# CH32V30xxx register map
Vendor: WCH Ltd.; File version: 1.0
Registers are 32-bit, read-write, reset 0x0 unless marked. A register's access mark holds for its fields unless they carry their own. Offsets are from the block's base; [hi:lo] are bit positions.

## FSMC — Flexible static memory controller
Base 0xA0000000
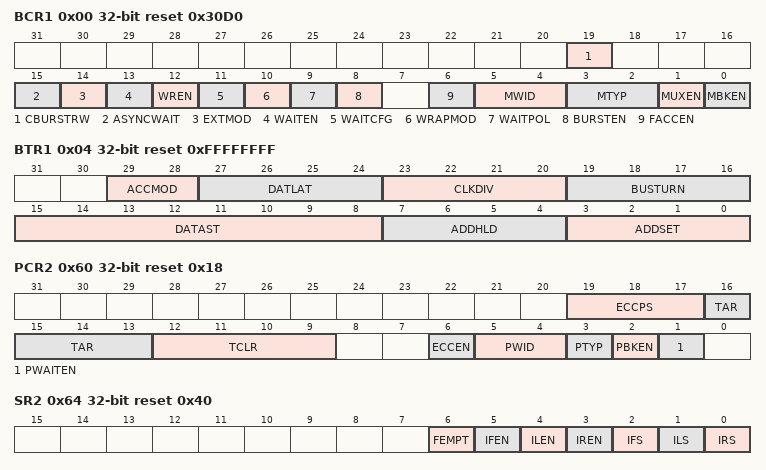
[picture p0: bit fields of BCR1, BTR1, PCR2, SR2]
0x00 BCR1 reset 0x30D0 — SRAM/NOR-Flash chip-select control register 1
  [19] CBURSTRW — Write burst enable
  [15] ASYNCWAIT — Wait signal during asynchronous transfers
  [14] EXTMOD — Extended mode enable
  [13] WAITEN — Wait enable bit
  [12] WREN — Write enable bit
  [11] WAITCFG — Wait timing configuration
  [10] WRAPMOD — Wrapped burst mode support
  [9] WAITPOL — Wait signal polarity bit
  [8] BURSTEN — Burst enable bit
  [6] FACCEN — Flash access enable
  [5:4] MWID — Memory databus width
  [3:2] MTYP — Memory type
  [1] MUXEN — Address/data multiplexing enable bit
  [0] MBKEN — Memory bank enable bit
0x04 BTR1 reset 0xFFFFFFFF — SRAM/NOR-Flash chip-select timing register 1
  [29:28] ACCMOD — Access mode
  [27:24] DATLAT — Data latency for synchronous NOR Flash memory
  [23:20] CLKDIV — Clock divide ratio (for FSMC_CLK signal)
  [19:16] BUSTURN — Bus turnaround phase duration
  [15:8] DATAST — Data-phase duration
  [7:4] ADDHLD — Address-hold phase duration
  [3:0] ADDSET — Address setup phase duration
0x60 PCR2 reset 0x18 — PC Card/NAND Flash control register 2
  [19:17] ECCPS — ECC page size
  [16:13] TAR — ALE to RE delay
  [12:9] TCLR — CLE to RE delay
  [6] ECCEN — ECC computation logic enable bit
  [5:4] PWID — Databus width
  [3] PTYP — Memory type
  [2] PBKEN — PC Card/NAND Flash memory bank enable bit
  [1] PWAITEN — Wait feature enable bit
0x64 SR2 access per field reset 0x40 — FIFO status and interrupt register 2
  [6] FEMPT ro — FIFO empty
  [5] IFEN rw — Interrupt falling edge detection enable bit
  [4] ILEN rw — Interrupt high-level detection enable bit
  [3] IREN rw — Interrupt rising edge detection enable bit
  [2] IFS rw — Interrupt falling edge status
  [1] ILS rw — Interrupt high-level status
  [0] IRS rw — Interrupt rising edge status
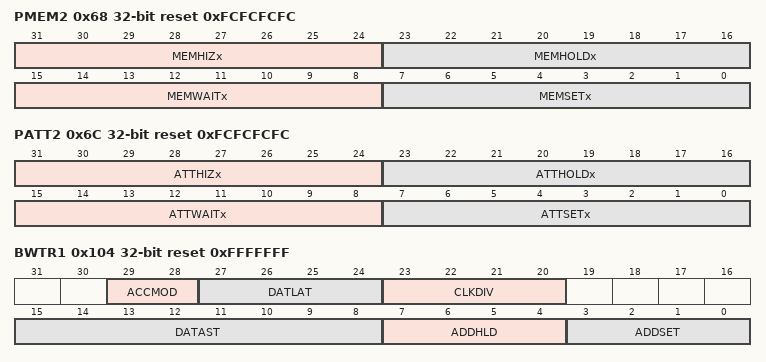
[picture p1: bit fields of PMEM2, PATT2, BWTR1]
0x68 PMEM2 reset 0xFCFCFCFC — Common memory space timing register 2
  [31:24] MEMHIZx — Common memory x databus HiZ time
  [23:16] MEMHOLDx — Common memory x hold time
  [15:8] MEMWAITx — Common memory x wait time
  [7:0] MEMSETx — Common memory x setup time
0x6C PATT2 reset 0xFCFCFCFC — Attribute memory space timing register 2
  [31:24] ATTHIZx — Attribute memory x databus HiZ time
  [23:16] ATTHOLDx — Attribute memory x hold time
  [15:8] ATTWAITx — Attribute memory x wait time
  [7:0] ATTSETx — Attribute memory x setup time
0x74 ECCR2 ro — ECC result register 2
  [31:0] ECCx — ECC result
0x104 BWTR1 reset 0xFFFFFFF — SRAM/NOR-Flash write timing registers 1
  [29:28] ACCMOD — Access mode
  [27:24] DATLAT — Data latency for synchronous NOR Flash memory
  [23:20] CLKDIV — Clock divide ratio (for FSMC_CLK signal)
  [15:8] DATAST — Data-phase duration
  [7:4] ADDHLD — Address-hold phase duration
  [3:0] ADDSET — Address setup phase duration

## DVP — Digital Video Port
Base 0x50050000
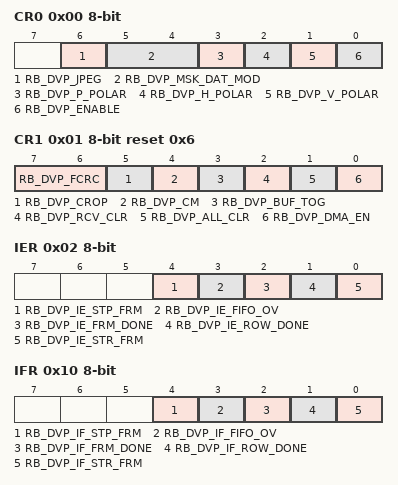
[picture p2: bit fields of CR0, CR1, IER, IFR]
0x00 CR0 8-bit — Digital Video control register (DVP_CR0)
  [6] RB_DVP_JPEG — DVP JPEG mode
  [5:4] RB_DVP_MSK_DAT_MOD — DVP data mode
  [3] RB_DVP_P_POLAR — DVP PCLK polarity control
  [2] RB_DVP_H_POLAR — DVP HSYNC polarity control
  [1] RB_DVP_V_POLAR — DVP VSYNC polarity control
  [0] RB_DVP_ENABLE — DVP enable
0x01 CR1 8-bit reset 0x6 — Digital Video control register (DVP_CR1)
  [7:6] RB_DVP_FCRC — DVP frame capture rate control
  [5] RB_DVP_CROP — DVP Crop feature enable
  [4] RB_DVP_CM — DVP capture mode
  [3] RB_DVP_BUF_TOG — DVP bug toggle by software
  [2] RB_DVP_RCV_CLR — DVP receive logic clear
  [1] RB_DVP_ALL_CLR — DVP all clear
  [0] RB_DVP_DMA_EN — DVP dma enable
0x02 IER 8-bit — Digital Video Interrupt register (DVP_IER)
  [4] RB_DVP_IE_STP_FRM — DVP frame stop interrupt enable
  [3] RB_DVP_IE_FIFO_OV — DVP receive fifo overflow interrupt enable
  [2] RB_DVP_IE_FRM_DONE — DVP frame received done interrupt enable
  [1] RB_DVP_IE_ROW_DONE — DVP row received done interrupt enable
  [0] RB_DVP_IE_STR_FRM — DVP frame start interrupt enable
0x04 ROW_NUM 16-bit — Image line count configuration register (DVP_ROW_NUM)
  [15:0] RB_DVP_ROW_NUM — The number of rows of frame image data
0x06 COL_NUM 16-bit — Image column number configuration register (DVP_COL_NUM)
  [15:0] RB_DVP_COL_NUM — Number of PCLK cycles for row data
0x08 DMA_BUF0 — Digital Video DMA address register (DVP_DMA_BUF0)
  [16:0] RB_DVP_DMA_BUF0 — DMA receive address 0
0x0C DMA_BUF1 — Digital Video DMA address register (DVP_DMA_BUF1)
  [16:0] RB_DVP_DMA_BUF1 — DMA receive address 1
0x10 IFR 8-bit — Digital Video Flag register (DVP_IFR)
  [4] RB_DVP_IF_STP_FRM — DVP frame stop interrupt enable
  [3] RB_DVP_IF_FIFO_OV — DVP receive fifo overflow interrupt enable
  [2] RB_DVP_IF_FRM_DONE — DVP frame received done interrupt enable
  [1] RB_DVP_IF_ROW_DONE — DVP row received done interrupt enable
  [0] RB_DVP_IF_STR_FRM — DVP frame start interrupt enable
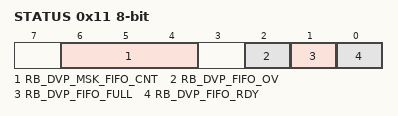
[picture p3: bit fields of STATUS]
0x11 STATUS 8-bit ro — Digital Video STATUS register (DVP_STATUS)
  [6:4] RB_DVP_MSK_FIFO_CNT — DVP receive fifo overflow interrupt enable
  [2] RB_DVP_FIFO_OV — DVP frame received done interrupt enable
  [1] RB_DVP_FIFO_FULL — DVP row received done interrupt enable
  [0] RB_DVP_FIFO_RDY — DVP frame start interrupt enable
0x14 ROW_CNT 16-bit ro — Digital Video line counter register (DVP_ROW_CNT)
  [15:0] RB_DVP_ROW_CNT — The number of rows of frame image data
0x18 HOFFCNT 16-bit — Digital Video horizontal displacement register (DVP_HOFFCNT)
  [15:0] RB_DVP_HOFFCNT — Number of PCLK cycles for row data
0x1A VST 16-bit — Digital Video line number register (DVP_VST)
  [15:0] RB_DVP_VST — The number of lines captured by the image
0x1C CAPCNT 16-bit — Digital Video Capture count register (DVP_CAPCNT)
  [15:0] RB_DVP_CAPCNT — Number of PCLK cycles captured by clipping window
0x1E VLINE 16-bit — Digital Video Vertical line count register (DVP_VLINE)
  [15:0] RB_DVP_VLINE — Crop the number of rows captured by window
0x20 DR ro — Digital Video Data register (DVP_DR)
  [31:0] RB_DVP_DR — Prevent DMA overflow
